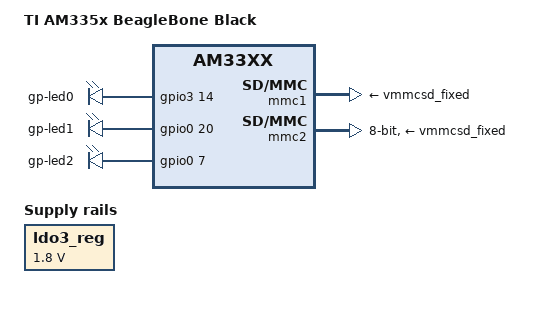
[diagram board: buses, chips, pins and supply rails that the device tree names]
/*
 * Copyright (C) 2012 Texas Instruments Incorporated - http://www.ti.com/
 *
 * This program is free software; you can redistribute it and/or modify
 * it under the terms of the GNU General Public License version 2 as
 * published by the Free Software Foundation.
 */
/dts-v1/;

#include "am33xx.dtsi"
#include "am335x-bone-common.dtsi"
/* #include "am335x-bone-jtag.dtsi" */

/ {
	model = "TI AM335x BeagleBone Black";
	compatible = "ti,am335x-bone-black", "ti,am335x-bone", "ti,am33xx";
};

&ldo3_reg {
	regulator-min-microvolt = <1800000>;
	regulator-max-microvolt = <1800000>;
	regulator-always-on;
};

&mmc1 {
	vmmc-supply = <&vmmcsd_fixed>;
};

&mmc2 {
	vmmc-supply = <&vmmcsd_fixed>;
	pinctrl-names = "default";
	pinctrl-0 = <&emmc_pins>;
	bus-width = <8>;
	status = "okay";
};

&cpu0_opp_table {
	/*
	 * All PG 2.0 silicon may not support 1GHz but some of the early
	 * BeagleBone Blacks have PG 2.0 silicon which is guaranteed
	 * to support 1GHz OPP so enable it for PG 2.0 on this board.
	 */
	oppnitro@1000000000 {
		opp-supported-hw = <0x06 0x0100>;
	};
};

#include "am335x-bone-pinmux-ttyS1.dtsi"
#include "am335x-bone-pinmux-ttyS2.dtsi"
#include "am335x-bone-pinmux-ttyS4.dtsi"
#include "am335x-bone-pinmux-ttyS5.dtsi"


/* Configuration of leds */
&am33xx_pinmux {
	gpleds_pins: pinmux_gpleds_pins {
		pinctrl-single,pins = <
			BONE_P9_31 (PIN_OUTPUT | MUX_MODE7)
			BONE_P9_41 (PIN_OUTPUT | MUX_MODE7)
			BONE_P9_42 (PIN_OUTPUT | MUX_MODE7)
		>;
	};
};

/ {
	gpleds {
		pinctrl-names = "default";
		pinctrl-0 = <&gpleds_pins>;

		compatible = "gpio-leds";

		gpled@0 {
			label = "gp-led0";
			gpios = <&gpio3 14 0>;
			linux,default-trigger = "heartbeat";
			default-state = "off";
		};

		gpled@1 {
			label = "gp-led1";
			gpios = <&gpio0 20 0>;
			linux,default-trigger = "none";
			default-state = "off";
		};

		gpled@2 {
			label = "gp-led2";
			gpios = <&gpio0 7 0>;
			linux,default-trigger = "none";
			default-state = "off";
		};
	};
};
